# AM335x register map
Vendor: Texas Instruments; Series: Sitara AM335x; File version: 1.1
CPU: Cortex-A8 r0p0, little endian
Registers are 32-bit, read-write, reset 0x0 unless marked. A register's access mark holds for its fields unless they carry their own. Offsets are from the block's base; [hi:lo] are bit positions; 'fields as' and 'values as' point back to an identical list.

## PRM_IRQ — Power Reset Module - IRQ
Base 0x44E00B00
0x00 REVISION
  [7:0] REV — IP revision [7:4] Major revision [3:0] Minor revision Examples: 0x10 for 1.0, 0x21 for 2.1
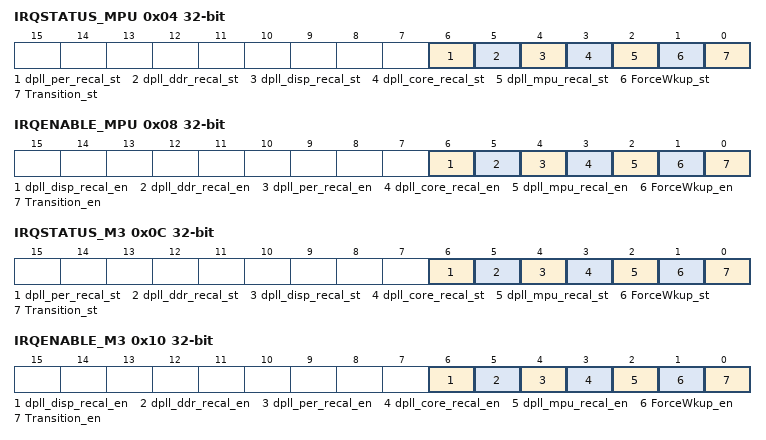
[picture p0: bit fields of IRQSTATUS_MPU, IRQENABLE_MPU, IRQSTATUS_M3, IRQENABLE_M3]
0x04 IRQSTATUS_MPU
  [6] dpll_per_recal_st — bit: 15 (RW)interrupt status for usb dpll recaliberation [0x0 = disable; 0x1 = enable;]
  [5] dpll_ddr_recal_st — bit: 14 (RW)interrupt status for ddr dpll recaliberation [0x0 = disable; 0x1 = enable;]
  [4] dpll_disp_recal_st — bit: 13 (RW)interrupt status for disp dpll recaliberation [0x0 = disable; 0x1 = enable;]
  [3] dpll_core_recal_st — bit: 12 (RW)interrupt status for core dpll recaliberation [0x0 = disable; 0x1 = enable;]
  [2] dpll_mpu_recal_st — bit: 11 (RW)interrupt status for mpu dpll recaliberation [0x0 = disable; 0x1 = enable;]
  [1] ForceWkup_st — bit: 10 (RW)Software supervised wakeup completed event interrupt status [0x0 = IRQ_fal : No interrupt; 0x1 = IRQ_tru : Interrupt is pending;]
  [0] Transition_st — bit: 8 (RW)Software supervised transition completed event interrupt status [0x0 = IRQ_fal : No interrupt; 0x1 = IRQ_tru : Interrupt is pending;]
0x08 IRQENABLE_MPU
  [6] dpll_disp_recal_en — bit: 15 (RW)interrupt status for usb dpll recaliberation [0x0 = disable ; 0x1 = enable ;]
  [5] dpll_ddr_recal_en — bit: 14 (RW)interrupt status for ddr dpll recaliberation [0x0 = disable ; 0x1 = enable ;]
  [4] dpll_per_recal_en — bit: 13 (RW)interrupt status for disp dpll recaliberation [0x0 = disable ; 0x1 = enable ;]
  [3] dpll_core_recal_en — bit: 12 (RW)interrupt status for core dpll recaliberation [0x0 = disable ; 0x1 = enable ;]
  [2] dpll_mpu_recal_en — bit: 11 (RW)Interrupt enable for mpu dpll recaliberation [0x0 = disable ; 0x1 = enable ;]
  [1] ForceWkup_en — bit: 10 (RW)Software supervised Froce Wakeup completed event interruptenable [0x0 = masked; 0x1 = enabled]
  [0] Transition_en — bit: 8 (RW)Software supervised transition completed event interrupt enable (anydomain) [0x0 = masked; 0x1 = enabled]
0x0C IRQSTATUS_M3
  fields as IRQSTATUS_MPU
0x10 IRQENABLE_M3
  fields as IRQENABLE_MPU

## PRM_MPU — Power Reset Module - MPU
Base 0x44E00E00
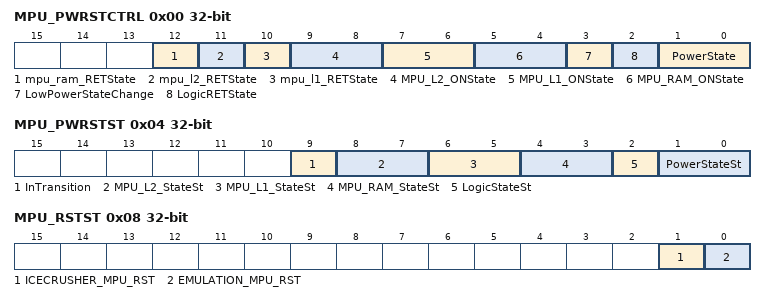
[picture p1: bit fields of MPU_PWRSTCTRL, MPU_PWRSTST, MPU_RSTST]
0x00 MPU_PWRSTCTRL
  [12] mpu_ram_RETState — bit: 24 (RW) Default power domain memory(L2) retention state when power domain is in retention
  [11] mpu_l2_RETState — bit: 23 (RW) Default power domain memory(L1) retention state when power domain is in retention
  [10] mpu_l1_RETState ro — bit: 22 Reserved
  [9:8] MPU_L2_ONState — bit: 20,21 (R) Default power domain memory state when domain is ON.
  [7:6] MPU_L1_ONState — bit: 18,19 (R) Default power domain memory state when domain is ON.
  [5:4] MPU_RAM_ONState — bit: 16,17 (RW) Default power domain memory state when domain is ON [see e_PWR_CTRL_MEM_STATE]
  [3] LowPowerStateChange — bit: 4 (RW) Power state change request when domain has already performed a sleep transition [0x0 = Do not request; 0x1 = Request a low power state change]
  [2] LogicRETState — bit: 2 (RW) Logic state when power domain is RETENTION [0x0 = logic_off; 0x1 = logic_ret]
  [1:0] PowerState — bit: 0,1 (RW) Power state control [see e_PWR_STATE_CTRL]
0x04 MPU_PWRSTST
  [9] InTransition — bit: 20 (R) Domain transition status [0x0 = No on-going transition; 0x1 = transition is in progress.]
  [8:7] MPU_L2_StateSt — bit: 8,9 (R) MPU L2 memory state status [see e_PWR_STATE_MEM_STS]
  [6:5] MPU_L1_StateSt — bit: 6,7 (R) MPU L1 memory state status [see e_PWR_STATE_MEM_STS]
  [4:3] MPU_RAM_StateSt — bit: 5,4 (R) MPU_RAM memory state status [see e_PWR_STATE_MEM_STS]
  [2] LogicStateSt — bit: 2 (R) Logic state status [0x0 = logic_off; 0x1 = logic_on]
  [1:0] PowerStateSt — bit: 0,1 (R) Current Power State Status [see e_PWR_STATE_STS]
0x08 MPU_RSTST
  [1] ICECRUSHER_MPU_RST — bit: 6 (RW) MPU Processor has been reset due to MPU ICECRUSHER1 resetevent [0x0 = RESET_NO; 0x1 = RESET_YES]
  [0] EMULATION_MPU_RST — bit: 5 (RW) MPU Processor has been reset due to emulation reset source e.g. assert reset command initiated by the icepick module [0x0 = RESET_NO; 0x1 = RESET_YES]
